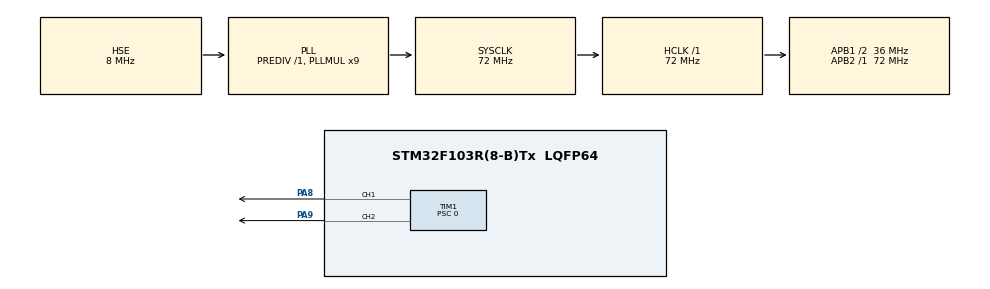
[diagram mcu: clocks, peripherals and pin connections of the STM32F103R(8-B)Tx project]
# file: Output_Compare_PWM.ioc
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Mcu.Family=STM32F1
Mcu.Name=STM32F103R(8-B)Tx
Mcu.Package=LQFP64
NVIC.PriorityGroup=NVIC_PRIORITYGROUP_4
PA13.Mode=Serial_Wire
PA13.Signal=SYS_JTMS-SWDIO
PA14.Mode=Serial_Wire
PA14.Signal=SYS_JTCK-SWCLK
PA8.Signal=S_TIM1_CH1
PA9.Signal=S_TIM1_CH2
PD0-OSC_IN.Mode=HSE-External-Clock-Source
PD0-OSC_IN.Signal=RCC_OSC_IN
PD1-OSC_OUT.Mode=HSE-External-Clock-Source
PD1-OSC_OUT.Signal=RCC_OSC_OUT
ProjectManager.HeapSize=0x200
ProjectManager.StackSize=0x400
ProjectManager.TargetToolchain=Makefile
RCC.AHBFreq_Value=72000000
RCC.APB1CLKDivider=RCC_HCLK_DIV2
RCC.APB1Freq_Value=36000000
RCC.APB1TimFreq_Value=72000000
RCC.APB2Freq_Value=72000000
RCC.APB2TimFreq_Value=72000000
RCC.HCLKFreq_Value=72000000
RCC.PLLMUL=RCC_PLL_MUL9
RCC.PLLSourceVirtual=RCC_PLLSOURCE_HSE
RCC.SYSCLKFreq_VALUE=72000000
RCC.SYSCLKSource=RCC_SYSCLKSOURCE_PLLCLK
RCC.USBFreq_Value=72000000
SH.S_TIM1_CH1.0=TIM1_CH1,PWM Generation1 CH1
SH.S_TIM1_CH2.0=TIM1_CH2,PWM Generation2 CH2
TIM1.Channel-PWM\ Generation1\ CH1=TIM_CHANNEL_1
TIM1.Channel-PWM\ Generation2\ CH2=TIM_CHANNEL_2
TIM1.Period=36000-1
TIM1.Prescaler=0
VP_TIM1_VS_ClockSourceINT.Mode=Internal
board=custom

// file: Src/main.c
/* USER CODE BEGIN Header */
/**
  ******************************************************************************
  * @file           : main.c
  * @brief          : Main program body
  ******************************************************************************
  * @attention
  *
  * <h2><center>&copy; Copyright (c) 2020 STMicroelectronics.
  * All rights reserved.</center></h2>
  *
  * This software component is licensed by ST under BSD 3-Clause license,
  * the "License"; You may not use this file except in compliance with the
  * License. You may obtain a copy of the License at:
  *                        opensource.org/licenses/BSD-3-Clause
  *
  ******************************************************************************
  */
/* USER CODE END Header */
#include "main.h"
#include "tim.h"
#include "gpio.h"

/* USER CODE BEGIN Includes */
#include "math.h"
/* USER CODE END Includes */

void SystemClock_Config(void);
/* USER CODE BEGIN PFP */

/**
 * @brief 按照L298N逻辑驱动电机。
 *        其中默认通道一输出高、通道二输出低时为正转
 *
 * @param duty 将要输出的占空比，范围在-1到1之间
 */
void drive(float duty);

/* USER CODE END PFP */

int main(void)
{

  /* MCU Configuration--------------------------------------------------------*/

  /* Reset of all peripherals, Initializes the Flash interface and the Systick. */
  HAL_Init();

  /* Configure the system clock */
  SystemClock_Config();

  /* Initialize all configured peripherals */
  MX_GPIO_Init();
  MX_TIM1_Init();
  /* USER CODE BEGIN 2 */
  HAL_TIM_PWM_Start(&htim1, TIM_CHANNEL_1);
  HAL_TIM_PWM_Start(&htim1, TIM_CHANNEL_2);
  /* USER CODE END 2 */

  /* Infinite loop */
  /* USER CODE BEGIN WHILE */
  float t = 0;
  while (1)
  {
    /* USER CODE END WHILE */

    /* USER CODE BEGIN 3 */
    t += 0.01;
    drive(sinf(t) * 0.5);
    HAL_Delay(10);

    if(t >= M_PI)
      t = -M_PI;
  }
  /* USER CODE END 3 */
}

void SystemClock_Config(void)
{
  RCC_OscInitTypeDef RCC_OscInitStruct = {0};
  RCC_ClkInitTypeDef RCC_ClkInitStruct = {0};

  /** Initializes the RCC Oscillators according to the specified parameters
  * in the RCC_OscInitTypeDef structure.
  */
  RCC_OscInitStruct.OscillatorType = RCC_OSCILLATORTYPE_HSE;
  RCC_OscInitStruct.HSEState = RCC_HSE_BYPASS;
  RCC_OscInitStruct.HSEPredivValue = RCC_HSE_PREDIV_DIV1;
  RCC_OscInitStruct.HSIState = RCC_HSI_ON;
  RCC_OscInitStruct.PLL.PLLState = RCC_PLL_ON;
  RCC_OscInitStruct.PLL.PLLSource = RCC_PLLSOURCE_HSE;
  RCC_OscInitStruct.PLL.PLLMUL = RCC_PLL_MUL9;
  if (HAL_RCC_OscConfig(&RCC_OscInitStruct) != HAL_OK)
  {
    Error_Handler();
  }
  /** Initializes the CPU, AHB and APB buses clocks
  */
  RCC_ClkInitStruct.ClockType = RCC_CLOCKTYPE_HCLK|RCC_CLOCKTYPE_SYSCLK
                              |RCC_CLOCKTYPE_PCLK1|RCC_CLOCKTYPE_PCLK2;
  RCC_ClkInitStruct.SYSCLKSource = RCC_SYSCLKSOURCE_PLLCLK;
  RCC_ClkInitStruct.AHBCLKDivider = RCC_SYSCLK_DIV1;
  RCC_ClkInitStruct.APB1CLKDivider = RCC_HCLK_DIV2;
  RCC_ClkInitStruct.APB2CLKDivider = RCC_HCLK_DIV1;

  if (HAL_RCC_ClockConfig(&RCC_ClkInitStruct, FLASH_LATENCY_2) != HAL_OK)
  {
    Error_Handler();
  }
}

/* USER CODE BEGIN 4 */

void drive(float duty)
{
  if(duty > 0)
  {
    // 占空比值为正，正向旋转，通道一输出PWM，通道二输出低电平
    __HAL_TIM_SET_COMPARE(&htim1, TIM_CHANNEL_1, (duty > 1 ? 1 : duty) * 36000);
    __HAL_TIM_SET_COMPARE(&htim1, TIM_CHANNEL_2, 0);
  }
  else if(duty < 0)
  {
    // 占空比值为负，反向旋转，通道一输出低电平，通道二输出PWM
    __HAL_TIM_SET_COMPARE(&htim1, TIM_CHANNEL_1, 0);
    __HAL_TIM_SET_COMPARE(&htim1, TIM_CHANNEL_2, (duty < -1 ? -1 : duty) * 36000);
  }
  else
  {
    // 占空比值为零，两路通道都输出低电平
    __HAL_TIM_SET_COMPARE(&htim1, TIM_CHANNEL_1, 0);
    __HAL_TIM_SET_COMPARE(&htim1, TIM_CHANNEL_2, 0);
  }
}

/* USER CODE END 4 */

void Error_Handler(void)
{
}

/************************ (C) COPYRIGHT STMicroelectronics *****END OF FILE****/
